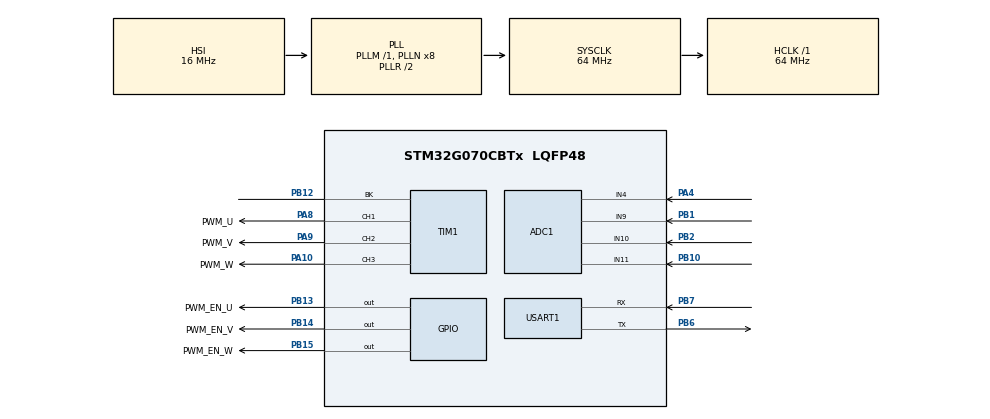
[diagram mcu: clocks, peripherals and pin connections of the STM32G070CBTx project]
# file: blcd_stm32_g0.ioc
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ADC1.Channel-0\#ChannelRegularConversion=ADC_CHANNEL_4
ADC1.Channel-4\#ChannelRegularConversion=ADC_CHANNEL_9
ADC1.Channel-5\#ChannelRegularConversion=ADC_CHANNEL_10
ADC1.Channel-6\#ChannelRegularConversion=ADC_CHANNEL_11
ADC1.DMAContinuousRequests=ENABLE
ADC1.DiscontinuousConvMode=ENABLE
ADC1.ExternalTrigConv=ADC_EXTERNALTRIG_T1_CC4
ADC1.NbrOfConversion=4
ADC1.NbrOfConversionFlag=1
ADC1.Overrun=ADC_OVR_DATA_OVERWRITTEN
ADC1.Rank-4\#ChannelRegularConversion=2
ADC1.Rank-5\#ChannelRegularConversion=3
ADC1.Rank-6\#ChannelRegularConversion=4
ADC1.SamplingTime-4\#ChannelRegularConversion=ADC_SAMPLINGTIME_COMMON_1
ADC1.SamplingTime-5\#ChannelRegularConversion=ADC_SAMPLINGTIME_COMMON_1
ADC1.SamplingTime-6\#ChannelRegularConversion=ADC_SAMPLINGTIME_COMMON_1
ADC1.SelectedChannel=ADC_CHANNEL_4|ADC_CHANNEL_9|ADC_CHANNEL_10|ADC_CHANNEL_11
ADC1.master=1
Dma.ADC1.0.Direction=DMA_PERIPH_TO_MEMORY
Dma.ADC1.0.EventEnable=DISABLE
Dma.ADC1.0.Instance=DMA1_Channel1
Dma.ADC1.0.MemDataAlignment=DMA_MDATAALIGN_HALFWORD
Dma.ADC1.0.MemInc=DMA_MINC_ENABLE
Dma.ADC1.0.Mode=DMA_CIRCULAR
Dma.ADC1.0.PeriphDataAlignment=DMA_PDATAALIGN_HALFWORD
Dma.ADC1.0.PeriphInc=DMA_PINC_DISABLE
Dma.ADC1.0.Polarity=HAL_DMAMUX_REQ_GEN_RISING
Dma.ADC1.0.Priority=DMA_PRIORITY_LOW
Dma.ADC1.0.RequestNumber=1
Dma.ADC1.0.SignalID=NONE
Dma.ADC1.0.SyncEnable=DISABLE
Dma.ADC1.0.SyncPolarity=HAL_DMAMUX_SYNC_NO_EVENT
Dma.ADC1.0.SyncRequestNumber=1
Dma.ADC1.0.SyncSignalID=NONE
Dma.Request0=ADC1
Mcu.Family=STM32G0
Mcu.Name=STM32G070CBTx
Mcu.Package=LQFP48
NVIC.DMA1_Channel1_IRQn=true\:0\:0\:false\:false\:true\:false\:true
NVIC.TIM1_BRK_UP_TRG_COM_IRQn=true\:0\:0\:false\:false\:true\:true\:true
PA10.GPIO_Label=PWM_W
PA10.Signal=S_TIM1_CH3
PA13.Mode=Serial_Wire
PA13.Signal=SYS_SWDIO
PA14-BOOT0.Mode=Serial_Wire
PA14-BOOT0.Signal=SYS_SWCLK
PA4.GPIO_Mode=GPIO_MODE_ANALOG
PA4.GPIO_PuPd=GPIO_NOPULL
PA4.Mode=IN4
PA4.Signal=ADC1_IN4
PA8.GPIO_Label=PWM_U
PA8.Signal=S_TIM1_CH1
PA9.GPIO_Label=PWM_V
PA9.Signal=S_TIM1_CH2
PB1.GPIO_Mode=GPIO_MODE_ANALOG
PB1.GPIO_PuPd=GPIO_NOPULL
PB1.Mode=IN9
PB1.Signal=ADC1_IN9
PB10.GPIO_Mode=GPIO_MODE_ANALOG
PB10.GPIO_PuPd=GPIO_NOPULL
PB10.Mode=IN11
PB10.Signal=ADC1_IN11
PB12.Mode=Activate-Break-Input
PB12.Signal=TIM1_BK
PB13.GPIO_Label=PWM_EN_U
PB13.Signal=GPIO_Output
PB14.GPIO_Label=PWM_EN_V
PB14.Signal=GPIO_Output
PB15.GPIO_Label=PWM_EN_W
PB15.Signal=GPIO_Output
PB2.GPIO_Mode=GPIO_MODE_ANALOG
PB2.GPIO_PuPd=GPIO_NOPULL
PB2.Mode=IN10
PB2.Signal=ADC1_IN10
PB6.Mode=Asynchronous
PB6.Signal=USART1_TX
PB7.Mode=Asynchronous
PB7.Signal=USART1_RX
PF0-OSC_IN\ (PF0).Mode=HSE-External-Oscillator
PF0-OSC_IN\ (PF0).Signal=RCC_OSC_IN
PF1-OSC_OUT\ (PF1).Mode=HSE-External-Oscillator
PF1-OSC_OUT\ (PF1).Signal=RCC_OSC_OUT
ProjectManager.HeapSize=0x200
ProjectManager.StackSize=0x400
ProjectManager.TargetToolchain=MDK-ARM V5.27
RCC.ADCFreq_Value=64000000
RCC.AHBFreq_Value=64000000
RCC.CortexFreq_Value=64000000
RCC.EXTERNAL_CLOCK_VALUE=48000
RCC.HCLKFreq_Value=64000000
RCC.HSE_VALUE=8000000
RCC.HSI_VALUE=16000000
RCC.LSE_VALUE=32768
RCC.SYSCLKFreq_VALUE=64000000
RCC.SYSCLKSource=RCC_SYSCLKSOURCE_PLLCLK
RCC.VCOOutputFreq_Value=128000000
SH.S_TIM1_CH1.0=TIM1_CH1,PWM Generation1 CH1
SH.S_TIM1_CH2.0=TIM1_CH2,PWM Generation2 CH2
SH.S_TIM1_CH3.0=TIM1_CH3,PWM Generation3 CH3
TIM1.AutoReloadPreload=TIM_AUTORELOAD_PRELOAD_DISABLE
TIM1.BreakPolarity=TIM_BREAKPOLARITY_LOW
TIM1.Channel-PWM\ Generation1\ CH1=TIM_CHANNEL_1
TIM1.Channel-PWM\ Generation2\ CH2=TIM_CHANNEL_2
TIM1.Channel-PWM\ Generation3\ CH3=TIM_CHANNEL_3
TIM1.Channel-PWM\ Generation4\ No\ Output=TIM_CHANNEL_4
TIM1.ClockDivision=TIM_CLOCKDIVISION_DIV2
TIM1.CounterMode=TIM_COUNTERMODE_CENTERALIGNED1
TIM1.OC1Preload_PWM=ENABLE
TIM1.Period=(64 * 1000000 / 10000 / 2)
TIM1.Pulse-PWM\ Generation1\ CH1=3200/2
TIM1.Pulse-PWM\ Generation2\ CH2=3200/2
TIM1.Pulse-PWM\ Generation3\ CH3=3200/2
TIM1.Pulse-PWM\ Generation4\ No\ Output=3200 - 1
TIM1.RepetitionCounter=1
USART1.VirtualMode-Asynchronous=VM_ASYNC
VP_SYS_VS_DBSignals.Mode=DisableDeadBatterySignals
VP_TIM1_VS_ClockSourceINT.Mode=Internal
VP_TIM1_VS_no_output4.Mode=PWM Generation4 No Output
board=custom

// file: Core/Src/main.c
/* USER CODE BEGIN Header */
/**
  ******************************************************************************
  * @file           : main.c
  * @brief          : Main program body
  ******************************************************************************
  * @attention
  *
  * <h2><center>&copy; Copyright (c) 2024 STMicroelectronics.
  * All rights reserved.</center></h2>
  *
  * This software component is licensed by ST under BSD 3-Clause license,
  * the "License"; You may not use this file except in compliance with the
  * License. You may obtain a copy of the License at:
  *                        opensource.org/licenses/BSD-3-Clause
  *
  ******************************************************************************
  */
/* USER CODE END Header */
#include "main.h"

ADC_HandleTypeDef hadc1;
DMA_HandleTypeDef hdma_adc1;

TIM_HandleTypeDef htim1;

UART_HandleTypeDef huart1;

void SystemClock_Config(void);
static void MX_GPIO_Init(void);
static void MX_DMA_Init(void);
static void MX_ADC1_Init(void);
static void MX_TIM1_Init(void);
static void MX_USART1_UART_Init(void);

/* USER CODE BEGIN 0 */
void app_init(void);
/* USER CODE END 0 */

int main(void)
{

  /* MCU Configuration--------------------------------------------------------*/

  /* Reset of all peripherals, Initializes the Flash interface and the Systick. */
  HAL_Init();

  /* Configure the system clock */
  SystemClock_Config();

  /* Initialize all configured peripherals */
  MX_GPIO_Init();
  MX_DMA_Init();
  MX_ADC1_Init();
  MX_TIM1_Init();
  MX_USART1_UART_Init();
  /* USER CODE BEGIN 2 */
  app_init();
  /* USER CODE END 2 */

  /* Infinite loop */
  while (1)
  {

  }
}

void SystemClock_Config(void)
{
  RCC_OscInitTypeDef RCC_OscInitStruct = {0};
  RCC_ClkInitTypeDef RCC_ClkInitStruct = {0};
  RCC_PeriphCLKInitTypeDef PeriphClkInit = {0};

  /** Configure the main internal regulator output voltage
  */
  HAL_PWREx_ControlVoltageScaling(PWR_REGULATOR_VOLTAGE_SCALE1);
  /** Initializes the RCC Oscillators according to the specified parameters
  * in the RCC_OscInitTypeDef structure.
  */
  RCC_OscInitStruct.OscillatorType = RCC_OSCILLATORTYPE_HSI;
  RCC_OscInitStruct.HSIState = RCC_HSI_ON;
  RCC_OscInitStruct.HSIDiv = RCC_HSI_DIV1;
  RCC_OscInitStruct.HSICalibrationValue = RCC_HSICALIBRATION_DEFAULT;
  RCC_OscInitStruct.PLL.PLLState = RCC_PLL_ON;
  RCC_OscInitStruct.PLL.PLLSource = RCC_PLLSOURCE_HSI;
  RCC_OscInitStruct.PLL.PLLM = RCC_PLLM_DIV1;
  RCC_OscInitStruct.PLL.PLLN = 8;
  RCC_OscInitStruct.PLL.PLLP = RCC_PLLP_DIV2;
  RCC_OscInitStruct.PLL.PLLR = RCC_PLLR_DIV2;
  if (HAL_RCC_OscConfig(&RCC_OscInitStruct) != HAL_OK)
  {
    Error_Handler();
  }
  /** Initializes the CPU, AHB and APB buses clocks
  */
  RCC_ClkInitStruct.ClockType = RCC_CLOCKTYPE_HCLK|RCC_CLOCKTYPE_SYSCLK
                              |RCC_CLOCKTYPE_PCLK1;
  RCC_ClkInitStruct.SYSCLKSource = RCC_SYSCLKSOURCE_PLLCLK;
  RCC_ClkInitStruct.AHBCLKDivider = RCC_SYSCLK_DIV1;
  RCC_ClkInitStruct.APB1CLKDivider = RCC_HCLK_DIV1;

  if (HAL_RCC_ClockConfig(&RCC_ClkInitStruct, FLASH_LATENCY_2) != HAL_OK)
  {
    Error_Handler();
  }
  /** Initializes the peripherals clocks
  */
  PeriphClkInit.PeriphClockSelection = RCC_PERIPHCLK_USART1|RCC_PERIPHCLK_ADC;
  PeriphClkInit.Usart1ClockSelection = RCC_USART1CLKSOURCE_PCLK1;
  PeriphClkInit.AdcClockSelection = RCC_ADCCLKSOURCE_SYSCLK;
  if (HAL_RCCEx_PeriphCLKConfig(&PeriphClkInit) != HAL_OK)
  {
    Error_Handler();
  }
}

static void MX_ADC1_Init(void)
{

  ADC_ChannelConfTypeDef sConfig = {0};

  /** Configure the global features of the ADC (Clock, Resolution, Data Alignment and number of conversion)
  */
  hadc1.Instance = ADC1;
  hadc1.Init.ClockPrescaler = ADC_CLOCK_SYNC_PCLK_DIV2;
  hadc1.Init.Resolution = ADC_RESOLUTION_12B;
  hadc1.Init.DataAlign = ADC_DATAALIGN_RIGHT;
  hadc1.Init.ScanConvMode = ADC_SCAN_ENABLE;
  hadc1.Init.EOCSelection = ADC_EOC_SINGLE_CONV;
  hadc1.Init.LowPowerAutoWait = DISABLE;
  hadc1.Init.LowPowerAutoPowerOff = DISABLE;
  hadc1.Init.ContinuousConvMode = DISABLE;
  hadc1.Init.NbrOfConversion = 4;
  hadc1.Init.DiscontinuousConvMode = ENABLE;
  hadc1.Init.ExternalTrigConv = ADC_EXTERNALTRIG_T1_CC4;
  hadc1.Init.ExternalTrigConvEdge = ADC_EXTERNALTRIGCONVEDGE_RISING;
  hadc1.Init.DMAContinuousRequests = ENABLE;
  hadc1.Init.Overrun = ADC_OVR_DATA_OVERWRITTEN;
  hadc1.Init.SamplingTimeCommon1 = ADC_SAMPLETIME_1CYCLE_5;
  hadc1.Init.SamplingTimeCommon2 = ADC_SAMPLETIME_1CYCLE_5;
  hadc1.Init.OversamplingMode = DISABLE;
  hadc1.Init.TriggerFrequencyMode = ADC_TRIGGER_FREQ_HIGH;
  if (HAL_ADC_Init(&hadc1) != HAL_OK)
  {
    Error_Handler();
  }
  /** Configure Regular Channel
  */
  sConfig.Channel = ADC_CHANNEL_4;
  sConfig.Rank = ADC_REGULAR_RANK_1;
  sConfig.SamplingTime = ADC_SAMPLINGTIME_COMMON_1;
  if (HAL_ADC_ConfigChannel(&hadc1, &sConfig) != HAL_OK)
  {
    Error_Handler();
  }
  /** Configure Regular Channel
  */
  sConfig.Channel = ADC_CHANNEL_9;
  sConfig.Rank = ADC_REGULAR_RANK_2;
  if (HAL_ADC_ConfigChannel(&hadc1, &sConfig) != HAL_OK)
  {
    Error_Handler();
  }
  /** Configure Regular Channel
  */
  sConfig.Channel = ADC_CHANNEL_10;
  sConfig.Rank = ADC_REGULAR_RANK_3;
  if (HAL_ADC_ConfigChannel(&hadc1, &sConfig) != HAL_OK)
  {
    Error_Handler();
  }
  /** Configure Regular Channel
  */
  sConfig.Channel = ADC_CHANNEL_11;
  sConfig.Rank = ADC_REGULAR_RANK_4;
  if (HAL_ADC_ConfigChannel(&hadc1, &sConfig) != HAL_OK)
  {
    Error_Handler();
  }

}

static void MX_TIM1_Init(void)
{

  TIM_ClockConfigTypeDef sClockSourceConfig = {0};
  TIM_MasterConfigTypeDef sMasterConfig = {0};
  TIMEx_BreakInputConfigTypeDef sBreakInputConfig = {0};
  TIM_OC_InitTypeDef sConfigOC = {0};
  TIM_BreakDeadTimeConfigTypeDef sBreakDeadTimeConfig = {0};

  htim1.Instance = TIM1;
  htim1.Init.Prescaler = 0;
  htim1.Init.CounterMode = TIM_COUNTERMODE_CENTERALIGNED1;
  htim1.Init.Period = (64 * 1000000 / 10000 / 2);
  htim1.Init.ClockDivision = TIM_CLOCKDIVISION_DIV2;
  htim1.Init.RepetitionCounter = 1;
  htim1.Init.AutoReloadPreload = TIM_AUTORELOAD_PRELOAD_DISABLE;
  if (HAL_TIM_Base_Init(&htim1) != HAL_OK)
  {
    Error_Handler();
  }
  sClockSourceConfig.ClockSource = TIM_CLOCKSOURCE_INTERNAL;
  if (HAL_TIM_ConfigClockSource(&htim1, &sClockSourceConfig) != HAL_OK)
  {
    Error_Handler();
  }
  if (HAL_TIM_PWM_Init(&htim1) != HAL_OK)
  {
    Error_Handler();
  }
  sMasterConfig.MasterOutputTrigger = TIM_TRGO_RESET;
  sMasterConfig.MasterOutputTrigger2 = TIM_TRGO2_RESET;
  sMasterConfig.MasterSlaveMode = TIM_MASTERSLAVEMODE_DISABLE;
  if (HAL_TIMEx_MasterConfigSynchronization(&htim1, &sMasterConfig) != HAL_OK)
  {
    Error_Handler();
  }
  sBreakInputConfig.Source = TIM_BREAKINPUTSOURCE_BKIN;
  sBreakInputConfig.Enable = TIM_BREAKINPUTSOURCE_ENABLE;
  sBreakInputConfig.Polarity = TIM_BREAKINPUTSOURCE_POLARITY_HIGH;
  if (HAL_TIMEx_ConfigBreakInput(&htim1, TIM_BREAKINPUT_BRK, &sBreakInputConfig) != HAL_OK)
  {
    Error_Handler();
  }
  sConfigOC.OCMode = TIM_OCMODE_PWM1;
  sConfigOC.Pulse = 3200/2;
  sConfigOC.OCPolarity = TIM_OCPOLARITY_HIGH;
  sConfigOC.OCNPolarity = TIM_OCNPOLARITY_HIGH;
  sConfigOC.OCFastMode = TIM_OCFAST_DISABLE;
  sConfigOC.OCIdleState = TIM_OCIDLESTATE_RESET;
  sConfigOC.OCNIdleState = TIM_OCNIDLESTATE_RESET;
  if (HAL_TIM_PWM_ConfigChannel(&htim1, &sConfigOC, TIM_CHANNEL_1) != HAL_OK)
  {
    Error_Handler();
  }
  if (HAL_TIM_PWM_ConfigChannel(&htim1, &sConfigOC, TIM_CHANNEL_2) != HAL_OK)
  {
    Error_Handler();
  }
  if (HAL_TIM_PWM_ConfigChannel(&htim1, &sConfigOC, TIM_CHANNEL_3) != HAL_OK)
  {
    Error_Handler();
  }
  sConfigOC.Pulse = 3200 - 1;
  if (HAL_TIM_PWM_ConfigChannel(&htim1, &sConfigOC, TIM_CHANNEL_4) != HAL_OK)
  {
    Error_Handler();
  }
  sBreakDeadTimeConfig.OffStateRunMode = TIM_OSSR_DISABLE;
  sBreakDeadTimeConfig.OffStateIDLEMode = TIM_OSSI_DISABLE;
  sBreakDeadTimeConfig.LockLevel = TIM_LOCKLEVEL_OFF;
  sBreakDeadTimeConfig.DeadTime = 0;
  sBreakDeadTimeConfig.BreakState = TIM_BREAK_ENABLE;
  sBreakDeadTimeConfig.BreakPolarity = TIM_BREAKPOLARITY_LOW;
  sBreakDeadTimeConfig.BreakFilter = 0;
  sBreakDeadTimeConfig.BreakAFMode = TIM_BREAK_AFMODE_INPUT;
  sBreakDeadTimeConfig.Break2State = TIM_BREAK2_DISABLE;
  sBreakDeadTimeConfig.Break2Polarity = TIM_BREAK2POLARITY_HIGH;
  sBreakDeadTimeConfig.Break2Filter = 0;
  sBreakDeadTimeConfig.Break2AFMode = TIM_BREAK_AFMODE_INPUT;
  sBreakDeadTimeConfig.AutomaticOutput = TIM_AUTOMATICOUTPUT_DISABLE;
  if (HAL_TIMEx_ConfigBreakDeadTime(&htim1, &sBreakDeadTimeConfig) != HAL_OK)
  {
    Error_Handler();
  }
  HAL_TIM_MspPostInit(&htim1);

}

static void MX_USART1_UART_Init(void)
{

  huart1.Instance = USART1;
  huart1.Init.BaudRate = 115200;
  huart1.Init.WordLength = UART_WORDLENGTH_8B;
  huart1.Init.StopBits = UART_STOPBITS_1;
  huart1.Init.Parity = UART_PARITY_NONE;
  huart1.Init.Mode = UART_MODE_TX_RX;
  huart1.Init.HwFlowCtl = UART_HWCONTROL_NONE;
  huart1.Init.OverSampling = UART_OVERSAMPLING_16;
  huart1.Init.OneBitSampling = UART_ONE_BIT_SAMPLE_DISABLE;
  huart1.Init.ClockPrescaler = UART_PRESCALER_DIV1;
  huart1.AdvancedInit.AdvFeatureInit = UART_ADVFEATURE_NO_INIT;
  if (HAL_UART_Init(&huart1) != HAL_OK)
  {
    Error_Handler();
  }
  if (HAL_UARTEx_SetTxFifoThreshold(&huart1, UART_TXFIFO_THRESHOLD_1_8) != HAL_OK)
  {
    Error_Handler();
  }
  if (HAL_UARTEx_SetRxFifoThreshold(&huart1, UART_RXFIFO_THRESHOLD_1_8) != HAL_OK)
  {
    Error_Handler();
  }
  if (HAL_UARTEx_DisableFifoMode(&huart1) != HAL_OK)
  {
    Error_Handler();
  }

}

static void MX_DMA_Init(void)
{

  /* DMA controller clock enable */
  __HAL_RCC_DMA1_CLK_ENABLE();

  /* DMA interrupt init */
  /* DMA1_Channel1_IRQn interrupt configuration */
  HAL_NVIC_SetPriority(DMA1_Channel1_IRQn, 0, 0);
  HAL_NVIC_EnableIRQ(DMA1_Channel1_IRQn);

}

static void MX_GPIO_Init(void)
{
  GPIO_InitTypeDef GPIO_InitStruct = {0};

  /* GPIO Ports Clock Enable */
  __HAL_RCC_GPIOF_CLK_ENABLE();
  __HAL_RCC_GPIOA_CLK_ENABLE();
  __HAL_RCC_GPIOB_CLK_ENABLE();

  /*Configure GPIO pin Output Level */
  HAL_GPIO_WritePin(GPIOB, PWM_EN_U_Pin|PWM_EN_V_Pin|PWM_EN_W_Pin, GPIO_PIN_RESET);

  /*Configure GPIO pins : PWM_EN_U_Pin PWM_EN_V_Pin PWM_EN_W_Pin */
  GPIO_InitStruct.Pin = PWM_EN_U_Pin|PWM_EN_V_Pin|PWM_EN_W_Pin;
  GPIO_InitStruct.Mode = GPIO_MODE_OUTPUT_PP;
  GPIO_InitStruct.Pull = GPIO_NOPULL;
  GPIO_InitStruct.Speed = GPIO_SPEED_FREQ_LOW;
  HAL_GPIO_Init(GPIOB, &GPIO_InitStruct);

}

void Error_Handler(void)
{
  __disable_irq();
  while (1)
  {
  }
}

/************************ (C) COPYRIGHT STMicroelectronics *****END OF FILE****/
